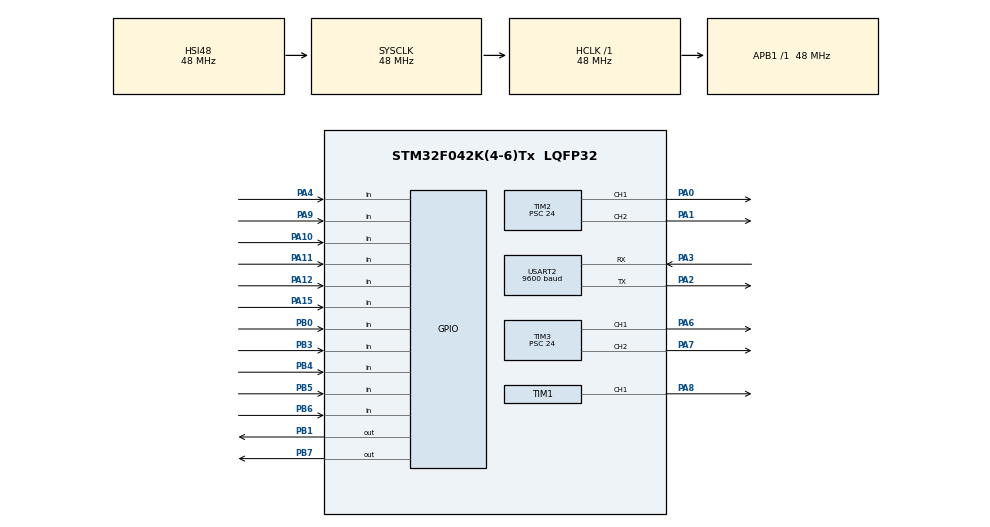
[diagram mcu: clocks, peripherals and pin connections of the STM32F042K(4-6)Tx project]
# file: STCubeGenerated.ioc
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Mcu.Family=STM32F0
Mcu.Name=STM32F042K(4-6)Tx
Mcu.Package=LQFP32
NVIC.TIM17_IRQn=true\:0\:0\:false\:false\:true\:false
NVIC.TimeBase=TIM17_IRQn
NVIC.TimeBaseIP=TIM17
NVIC.USART2_IRQn=true\:0\:0\:false\:false\:true\:true
PA0.Signal=S_TIM2_CH1_ETR
PA1.Signal=S_TIM2_CH2
PA10.Signal=GPIO_Input
PA11.Signal=GPIO_Input
PA12.Signal=GPIO_Input
PA15.Signal=GPIO_Input
PA2.Mode=Asynchronous
PA2.Signal=USART2_TX
PA3.Mode=Asynchronous
PA3.Signal=USART2_RX
PA4.Signal=GPIO_Input
PA6.Signal=S_TIM3_CH1
PA7.Signal=S_TIM3_CH2
PA8.Signal=S_TIM1_CH1
PA9.Signal=GPIO_Input
PB0.GPIO_PuPd=GPIO_PULLUP
PB0.Signal=GPIO_Input
PB1.Signal=GPIO_Output
PB3.Signal=GPIO_Input
PB4.Signal=GPIO_Input
PB5.Signal=GPIO_Input
PB6.GPIO_PuPd=GPIO_PULLUP
PB6.Signal=GPIO_Input
PB7.Signal=GPIO_Output
ProjectManager.HeapSize=0x200
ProjectManager.StackSize=0x400
ProjectManager.TargetToolchain=MDK-ARM V5
RCC.AHBFreq_Value=48000000
RCC.APB1Freq_Value=48000000
RCC.APB1TimFreq_Value=48000000
RCC.HCLKFreq_Value=48000000
RCC.SYSCLKFreq_VALUE=48000000
RCC.SYSCLKSource=RCC_SYSCLKSOURCE_HSI48
SH.S_TIM1_CH1.0=TIM1_CH1,PWM Generation1 CH1
SH.S_TIM2_CH1_ETR.0=TIM2_CH1,PWM Generation1 CH1
SH.S_TIM2_CH2.0=TIM2_CH2,PWM Generation2 CH2
SH.S_TIM3_CH1.0=TIM3_CH1,PWM Generation1 CH1
SH.S_TIM3_CH2.0=TIM3_CH2,PWM Generation2 CH2
TIM1.Channel-PWM\ Generation1\ CH1=TIM_CHANNEL_1
TIM1.Period=1000
TIM1.Prescaler=960
TIM14.Period=32000
TIM14.Prescaler=10
TIM2.Channel-PWM\ Generation1\ CH1=TIM_CHANNEL_1
TIM2.Channel-PWM\ Generation2\ CH2=TIM_CHANNEL_2
TIM2.Period=1000
TIM2.Prescaler=24
TIM3.Channel-PWM\ Generation1\ CH1=TIM_CHANNEL_1
TIM3.Channel-PWM\ Generation2\ CH2=TIM_CHANNEL_2
TIM3.Period=1000
TIM3.Prescaler=24
USART2.BaudRate=9600
USART2.VirtualMode-Asynchronous=VM_ASYNC
VP_SYS_VS_tim17.Mode=TIM17
VP_TIM14_VS_ClockSourceINT.Mode=Enable_Timer
VP_TIM1_VS_ClockSourceINT.Mode=Internal
VP_TIM2_VS_ClockSourceINT.Mode=Internal
VP_TIM3_VS_ClockSourceINT.Mode=Internal
board=custom

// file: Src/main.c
/* USER CODE END Header */

#include "main.h"

/* USER CODE BEGIN Includes */
#define osObjectsPublic                     // define objects in main module
#include "osObjects.h"                      // RTOS object definitions
#include "VELOCISTA.h"
/* USER CODE END Includes */

TIM_HandleTypeDef htim1;
TIM_HandleTypeDef htim2;
TIM_HandleTypeDef htim3;
TIM_HandleTypeDef htim14;

UART_HandleTypeDef huart2;

void SystemClock_Config(void);
static void MX_GPIO_Init(void);
static void MX_TIM1_Init(void);
static void MX_TIM2_Init(void);
static void MX_TIM3_Init(void);
static void MX_TIM14_Init(void);
static void MX_USART2_UART_Init(void);

int main(void)
{
  HAL_Init();

  SystemClock_Config();

  MX_GPIO_Init();
  MX_TIM1_Init();
  MX_TIM2_Init();
  MX_TIM3_Init();
  MX_TIM14_Init();
  MX_USART2_UART_Init();

  osKernelInitialize ();                    // initialize CMSIS-RTOS
	Init_Thread_Sensores();
  osKernelStart ();                         // start thread execution

  while (1)
  {

    Thread_Control ();

  }

}

void SystemClock_Config(void)
{
  RCC_OscInitTypeDef RCC_OscInitStruct = {0};
  RCC_ClkInitTypeDef RCC_ClkInitStruct = {0};

  /**Initializes the CPU, AHB and APB busses clocks
  */
  RCC_OscInitStruct.OscillatorType = RCC_OSCILLATORTYPE_HSI48;
  RCC_OscInitStruct.HSI48State = RCC_HSI48_ON;
  RCC_OscInitStruct.PLL.PLLState = RCC_PLL_NONE;
  if (HAL_RCC_OscConfig(&RCC_OscInitStruct) != HAL_OK)
  {
    Error_Handler();
  }
  /**Initializes the CPU, AHB and APB busses clocks
  */
  RCC_ClkInitStruct.ClockType = RCC_CLOCKTYPE_HCLK|RCC_CLOCKTYPE_SYSCLK
                              |RCC_CLOCKTYPE_PCLK1;
  RCC_ClkInitStruct.SYSCLKSource = RCC_SYSCLKSOURCE_HSI48;
  RCC_ClkInitStruct.AHBCLKDivider = RCC_SYSCLK_DIV1;
  RCC_ClkInitStruct.APB1CLKDivider = RCC_HCLK_DIV1;

  if (HAL_RCC_ClockConfig(&RCC_ClkInitStruct, FLASH_LATENCY_1) != HAL_OK)
  {
    Error_Handler();
  }
}

static void MX_TIM1_Init(void)
{

  TIM_ClockConfigTypeDef sClockSourceConfig = {0};
  TIM_MasterConfigTypeDef sMasterConfig = {0};
  TIM_OC_InitTypeDef sConfigOC = {0};
  TIM_BreakDeadTimeConfigTypeDef sBreakDeadTimeConfig = {0};

  htim1.Instance = TIM1;
  htim1.Init.Prescaler = 960;
  htim1.Init.CounterMode = TIM_COUNTERMODE_UP;
  htim1.Init.Period = 1000;
  htim1.Init.ClockDivision = TIM_CLOCKDIVISION_DIV1;
  htim1.Init.RepetitionCounter = 0;
  htim1.Init.AutoReloadPreload = TIM_AUTORELOAD_PRELOAD_DISABLE;
  if (HAL_TIM_Base_Init(&htim1) != HAL_OK)
  {
    Error_Handler();
  }
  sClockSourceConfig.ClockSource = TIM_CLOCKSOURCE_INTERNAL;
  if (HAL_TIM_ConfigClockSource(&htim1, &sClockSourceConfig) != HAL_OK)
  {
    Error_Handler();
  }
  if (HAL_TIM_PWM_Init(&htim1) != HAL_OK)
  {
    Error_Handler();
  }
  sMasterConfig.MasterOutputTrigger = TIM_TRGO_RESET;
  sMasterConfig.MasterSlaveMode = TIM_MASTERSLAVEMODE_DISABLE;
  if (HAL_TIMEx_MasterConfigSynchronization(&htim1, &sMasterConfig) != HAL_OK)
  {
    Error_Handler();
  }
  sConfigOC.OCMode = TIM_OCMODE_PWM1;
  sConfigOC.Pulse = 0;
  sConfigOC.OCPolarity = TIM_OCPOLARITY_HIGH;
  sConfigOC.OCNPolarity = TIM_OCNPOLARITY_HIGH;
  sConfigOC.OCFastMode = TIM_OCFAST_DISABLE;
  sConfigOC.OCIdleState = TIM_OCIDLESTATE_RESET;
  sConfigOC.OCNIdleState = TIM_OCNIDLESTATE_RESET;
  if (HAL_TIM_PWM_ConfigChannel(&htim1, &sConfigOC, TIM_CHANNEL_1) != HAL_OK)
  {
    Error_Handler();
  }
  sBreakDeadTimeConfig.OffStateRunMode = TIM_OSSR_DISABLE;
  sBreakDeadTimeConfig.OffStateIDLEMode = TIM_OSSI_DISABLE;
  sBreakDeadTimeConfig.LockLevel = TIM_LOCKLEVEL_OFF;
  sBreakDeadTimeConfig.DeadTime = 0;
  sBreakDeadTimeConfig.BreakState = TIM_BREAK_DISABLE;
  sBreakDeadTimeConfig.BreakPolarity = TIM_BREAKPOLARITY_HIGH;
  sBreakDeadTimeConfig.AutomaticOutput = TIM_AUTOMATICOUTPUT_DISABLE;
  if (HAL_TIMEx_ConfigBreakDeadTime(&htim1, &sBreakDeadTimeConfig) != HAL_OK)
  {
    Error_Handler();
  }
  HAL_TIM_MspPostInit(&htim1);

}

static void MX_TIM2_Init(void)
{

  TIM_ClockConfigTypeDef sClockSourceConfig = {0};
  TIM_MasterConfigTypeDef sMasterConfig = {0};
  TIM_OC_InitTypeDef sConfigOC = {0};

  htim2.Instance = TIM2;
  htim2.Init.Prescaler = 48;
  htim2.Init.CounterMode = TIM_COUNTERMODE_UP;
  htim2.Init.Period = 1000;
  htim2.Init.ClockDivision = TIM_CLOCKDIVISION_DIV1;
  htim2.Init.AutoReloadPreload = TIM_AUTORELOAD_PRELOAD_DISABLE;
  if (HAL_TIM_Base_Init(&htim2) != HAL_OK)
  {
    Error_Handler();
  }
  sClockSourceConfig.ClockSource = TIM_CLOCKSOURCE_INTERNAL;
  if (HAL_TIM_ConfigClockSource(&htim2, &sClockSourceConfig) != HAL_OK)
  {
    Error_Handler();
  }
  if (HAL_TIM_PWM_Init(&htim2) != HAL_OK)
  {
    Error_Handler();
  }
  sMasterConfig.MasterOutputTrigger = TIM_TRGO_RESET;
  sMasterConfig.MasterSlaveMode = TIM_MASTERSLAVEMODE_DISABLE;
  if (HAL_TIMEx_MasterConfigSynchronization(&htim2, &sMasterConfig) != HAL_OK)
  {
    Error_Handler();
  }
  sConfigOC.OCMode = TIM_OCMODE_PWM1;
  sConfigOC.Pulse = 0;
  sConfigOC.OCPolarity = TIM_OCPOLARITY_HIGH;
  sConfigOC.OCFastMode = TIM_OCFAST_DISABLE;
  if (HAL_TIM_PWM_ConfigChannel(&htim2, &sConfigOC, TIM_CHANNEL_1) != HAL_OK)
  {
    Error_Handler();
  }
  if (HAL_TIM_PWM_ConfigChannel(&htim2, &sConfigOC, TIM_CHANNEL_2) != HAL_OK)
  {
    Error_Handler();
  }
  HAL_TIM_MspPostInit(&htim2);

}

static void MX_TIM3_Init(void)
{

  TIM_ClockConfigTypeDef sClockSourceConfig = {0};
  TIM_MasterConfigTypeDef sMasterConfig = {0};
  TIM_OC_InitTypeDef sConfigOC = {0};

  htim3.Instance = TIM3;
  htim3.Init.Prescaler = 48;
  htim3.Init.CounterMode = TIM_COUNTERMODE_UP;
  htim3.Init.Period = 1000;
  htim3.Init.ClockDivision = TIM_CLOCKDIVISION_DIV1;
  htim3.Init.AutoReloadPreload = TIM_AUTORELOAD_PRELOAD_DISABLE;
  if (HAL_TIM_Base_Init(&htim3) != HAL_OK)
  {
    Error_Handler();
  }
  sClockSourceConfig.ClockSource = TIM_CLOCKSOURCE_INTERNAL;
  if (HAL_TIM_ConfigClockSource(&htim3, &sClockSourceConfig) != HAL_OK)
  {
    Error_Handler();
  }
  if (HAL_TIM_PWM_Init(&htim3) != HAL_OK)
  {
    Error_Handler();
  }
  sMasterConfig.MasterOutputTrigger = TIM_TRGO_RESET;
  sMasterConfig.MasterSlaveMode = TIM_MASTERSLAVEMODE_DISABLE;
  if (HAL_TIMEx_MasterConfigSynchronization(&htim3, &sMasterConfig) != HAL_OK)
  {
    Error_Handler();
  }
  sConfigOC.OCMode = TIM_OCMODE_PWM1;
  sConfigOC.Pulse = 0;
  sConfigOC.OCPolarity = TIM_OCPOLARITY_HIGH;
  sConfigOC.OCFastMode = TIM_OCFAST_DISABLE;
  if (HAL_TIM_PWM_ConfigChannel(&htim3, &sConfigOC, TIM_CHANNEL_1) != HAL_OK)
  {
    Error_Handler();
  }
  if (HAL_TIM_PWM_ConfigChannel(&htim3, &sConfigOC, TIM_CHANNEL_2) != HAL_OK)
  {
    Error_Handler();
  }
  HAL_TIM_MspPostInit(&htim3);

}

static void MX_TIM14_Init(void)
{

  htim14.Instance = TIM14;
  htim14.Init.Prescaler = 48;
  htim14.Init.CounterMode = TIM_COUNTERMODE_UP;
  htim14.Init.Period = 32000;
  htim14.Init.ClockDivision = TIM_CLOCKDIVISION_DIV1;
  htim14.Init.AutoReloadPreload = TIM_AUTORELOAD_PRELOAD_DISABLE;
  if (HAL_TIM_Base_Init(&htim14) != HAL_OK)
  {
    Error_Handler();
  }

}

static void MX_USART2_UART_Init(void)
{

  huart2.Instance = USART2;
  huart2.Init.BaudRate = 115200;
  huart2.Init.WordLength = UART_WORDLENGTH_8B;
  huart2.Init.StopBits = UART_STOPBITS_1;
  huart2.Init.Parity = UART_PARITY_NONE;
  huart2.Init.Mode = UART_MODE_TX_RX;
  huart2.Init.HwFlowCtl = UART_HWCONTROL_NONE;
  huart2.Init.OverSampling = UART_OVERSAMPLING_16;
  huart2.Init.OneBitSampling = UART_ONE_BIT_SAMPLE_DISABLE;
  huart2.AdvancedInit.AdvFeatureInit = UART_ADVFEATURE_NO_INIT;
  if (HAL_UART_Init(&huart2) != HAL_OK)
  {
    Error_Handler();
  }

}

static void MX_GPIO_Init(void)
{
  GPIO_InitTypeDef GPIO_InitStruct = {0};

  /* GPIO Ports Clock Enable */
  __HAL_RCC_GPIOA_CLK_ENABLE();
  __HAL_RCC_GPIOB_CLK_ENABLE();

  /*Configure GPIO pin Output Level */
  HAL_GPIO_WritePin(GPIOB, GPIO_PIN_1|GPIO_PIN_7, GPIO_PIN_RESET);

  /*Configure GPIO pins : PA4 PA9 PA10 PA11
                           PA12 PA15 */
  GPIO_InitStruct.Pin = GPIO_PIN_4|GPIO_PIN_9|GPIO_PIN_10|GPIO_PIN_11
                          |GPIO_PIN_12|GPIO_PIN_15;
  GPIO_InitStruct.Mode = GPIO_MODE_INPUT;
  GPIO_InitStruct.Pull = GPIO_NOPULL;
  HAL_GPIO_Init(GPIOA, &GPIO_InitStruct);

  /*Configure GPIO pins : PB0 PB6 */
  GPIO_InitStruct.Pin = GPIO_PIN_0|GPIO_PIN_6;
  GPIO_InitStruct.Mode = GPIO_MODE_INPUT;
  GPIO_InitStruct.Pull = GPIO_PULLUP;
  HAL_GPIO_Init(GPIOB, &GPIO_InitStruct);

  /*Configure GPIO pins : PB1 PB7 */
  GPIO_InitStruct.Pin = GPIO_PIN_1|GPIO_PIN_7;
  GPIO_InitStruct.Mode = GPIO_MODE_OUTPUT_PP;
  GPIO_InitStruct.Pull = GPIO_NOPULL;
  GPIO_InitStruct.Speed = GPIO_SPEED_FREQ_LOW;
  HAL_GPIO_Init(GPIOB, &GPIO_InitStruct);

  /*Configure GPIO pins : PB3 PB4 PB5 */
  GPIO_InitStruct.Pin = GPIO_PIN_3|GPIO_PIN_4|GPIO_PIN_5;
  GPIO_InitStruct.Mode = GPIO_MODE_INPUT;
  GPIO_InitStruct.Pull = GPIO_NOPULL;
  HAL_GPIO_Init(GPIOB, &GPIO_InitStruct);

}

void HAL_TIM_PeriodElapsedCallback(TIM_HandleTypeDef *htim)
{
  if (htim->Instance == TIM17) {
    HAL_IncTick();
  }
}

void Error_Handler(void)
{
}

/************************ (C) COPYRIGHT STMicroelectronics *****END OF FILE****/
